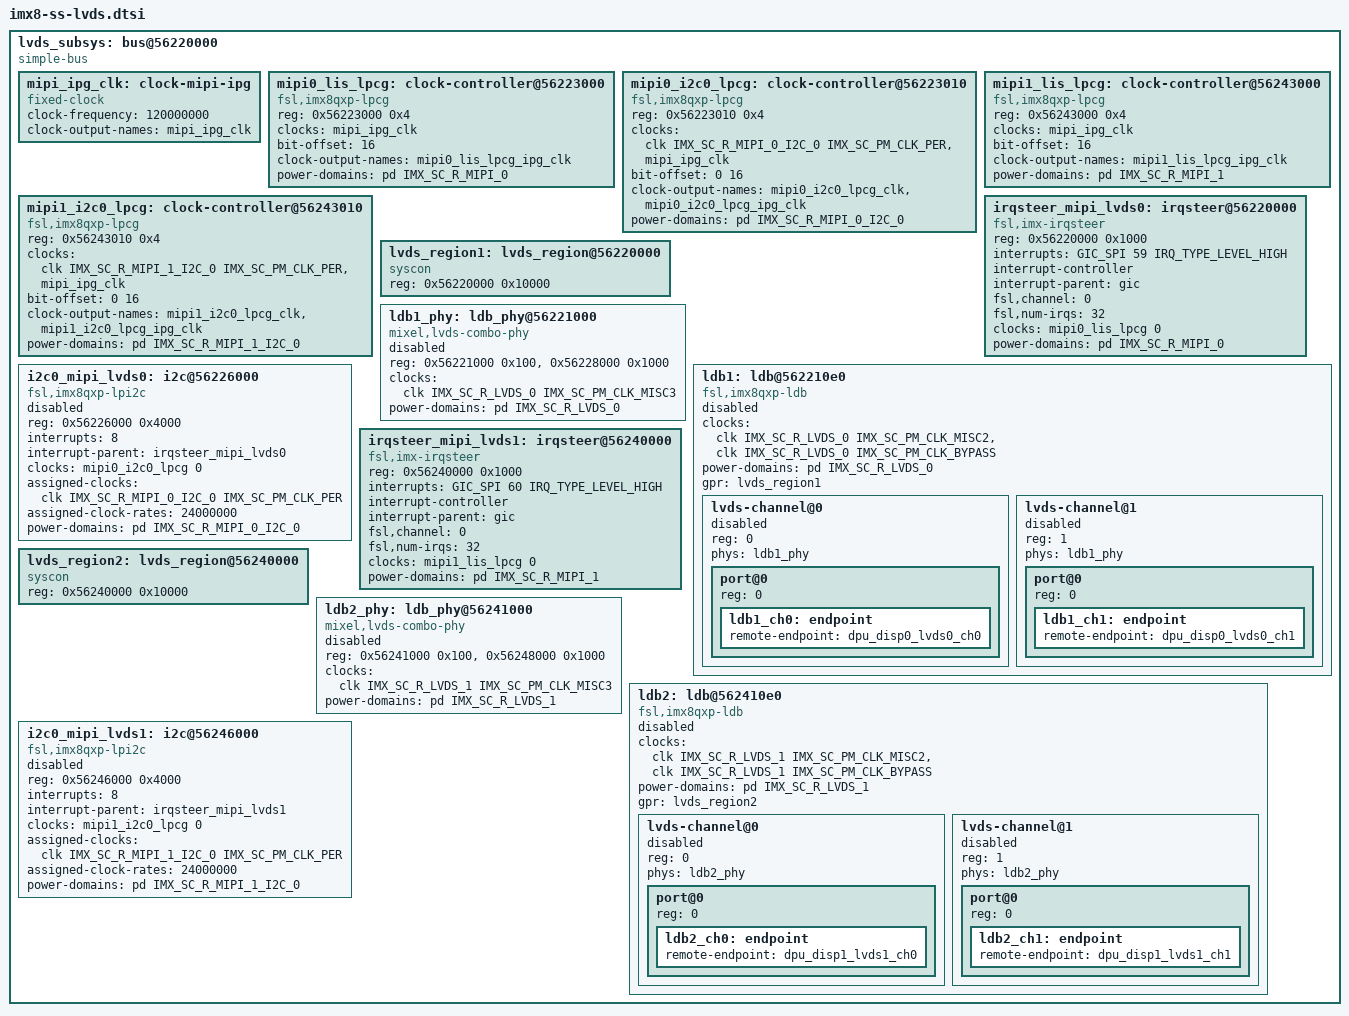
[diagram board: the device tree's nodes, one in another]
// SPDX-License-Identifier: GPL-2.0+
/*
 * Copyright 2019 NXP
 */

lvds_subsys: bus@56220000 {
	compatible = "simple-bus";
	#address-cells = <1>;
	#size-cells = <1>;
	ranges = <0x56220000 0x0 0x56220000 0x30000>;

	mipi_ipg_clk: clock-mipi-ipg {
		compatible = "fixed-clock";
		#clock-cells = <0>;
		clock-frequency = <120000000>;
		clock-output-names = "mipi_ipg_clk";
	};

	mipi0_lis_lpcg: clock-controller@56223000 {
		compatible = "fsl,imx8qxp-lpcg";
		reg = <0x56223000 0x4>;
		#clock-cells = <1>;
		clocks = <&mipi_ipg_clk>;
		bit-offset = <16>;
		clock-output-names = "mipi0_lis_lpcg_ipg_clk";
		power-domains = <&pd IMX_SC_R_MIPI_0>;
	};

	mipi0_i2c0_lpcg: clock-controller@56223010 {
		compatible = "fsl,imx8qxp-lpcg";
		reg = <0x56223010 0x4>;
		#clock-cells = <1>;
		clocks = <&clk IMX_SC_R_MIPI_0_I2C_0 IMX_SC_PM_CLK_PER>,
			 <&mipi_ipg_clk>;
		bit-offset = <0 16>;
		clock-output-names = "mipi0_i2c0_lpcg_clk",
				     "mipi0_i2c0_lpcg_ipg_clk";
		power-domains = <&pd IMX_SC_R_MIPI_0_I2C_0>;
	};

	mipi1_lis_lpcg: clock-controller@56243000 {
		compatible = "fsl,imx8qxp-lpcg";
		reg = <0x56243000 0x4>;
		#clock-cells = <1>;
		clocks = <&mipi_ipg_clk>;
		bit-offset = <16>;
		clock-output-names = "mipi1_lis_lpcg_ipg_clk";
		power-domains = <&pd IMX_SC_R_MIPI_1>;
	};

	mipi1_i2c0_lpcg: clock-controller@56243010 {
		compatible = "fsl,imx8qxp-lpcg";
		reg = <0x56243010 0x4>;
		#clock-cells = <1>;
		clocks = <&clk IMX_SC_R_MIPI_1_I2C_0 IMX_SC_PM_CLK_PER>,
			 <&mipi_ipg_clk>;
		bit-offset = <0 16>;
		clock-output-names = "mipi1_i2c0_lpcg_clk",
				     "mipi1_i2c0_lpcg_ipg_clk";
		power-domains = <&pd IMX_SC_R_MIPI_1_I2C_0>;
	};

	irqsteer_mipi_lvds0: irqsteer@56220000 {
		compatible = "fsl,imx-irqsteer";
		reg = <0x56220000 0x1000>;
		interrupts = <GIC_SPI 59 IRQ_TYPE_LEVEL_HIGH>;
		interrupt-controller;
		interrupt-parent = <&gic>;
		#interrupt-cells = <1>;
		fsl,channel = <0>;
		fsl,num-irqs = <32>;
		clocks = <&mipi0_lis_lpcg 0>;
		clock-names = "ipg";
		power-domains = <&pd IMX_SC_R_MIPI_0>;
	};

	lvds_region1: lvds_region@56220000 {
		compatible = "syscon";
		reg = <0x56220000 0x10000>;
	};

	ldb1_phy: ldb_phy@56221000 {
		compatible = "mixel,lvds-combo-phy";
		reg = <0x56221000 0x100>, <0x56228000 0x1000>;
		#phy-cells = <0>;
		clocks = <&clk IMX_SC_R_LVDS_0 IMX_SC_PM_CLK_MISC3>;
		clock-names = "phy";
		power-domains = <&pd IMX_SC_R_LVDS_0>;
		status = "disabled";
	};

	ldb1: ldb@562210e0 {
		#address-cells = <1>;
		#size-cells = <0>;
		compatible = "fsl,imx8qxp-ldb";
		clocks = <&clk IMX_SC_R_LVDS_0 IMX_SC_PM_CLK_MISC2>,
			 <&clk IMX_SC_R_LVDS_0 IMX_SC_PM_CLK_BYPASS>;
		clock-names = "pixel", "bypass";
		power-domains = <&pd IMX_SC_R_LVDS_0>;
		gpr = <&lvds_region1>;
		status = "disabled";

		lvds-channel@0 {
			#address-cells = <1>;
			#size-cells = <0>;
			reg = <0>;
			phys = <&ldb1_phy>;
			phy-names = "ldb_phy";
			status = "disabled";

			port@0 {
				reg = <0>;

				ldb1_ch0: endpoint {
					remote-endpoint = <&dpu_disp0_lvds0_ch0>;
				};
			};
		};

		lvds-channel@1 {
			#address-cells = <1>;
			#size-cells = <0>;
			reg = <1>;
			phys = <&ldb1_phy>;
			phy-names = "ldb_phy";
			status = "disabled";

			port@0 {
				reg = <0>;

				ldb1_ch1: endpoint {
					remote-endpoint = <&dpu_disp0_lvds0_ch1>;
				};
			};
		};
	};

	i2c0_mipi_lvds0: i2c@56226000 {
		compatible = "fsl,imx8qxp-lpi2c", "fsl,imx7ulp-lpi2c";
		reg = <0x56226000 0x4000>;
		interrupts = <8>;
		interrupt-parent = <&irqsteer_mipi_lvds0>;
		clocks = <&mipi0_i2c0_lpcg 0>;
		clock-names = "per";
		assigned-clocks = <&clk IMX_SC_R_MIPI_0_I2C_0 IMX_SC_PM_CLK_PER>;
		assigned-clock-rates = <24000000>;
		power-domains = <&pd IMX_SC_R_MIPI_0_I2C_0>;
		status = "disabled";
	};

	irqsteer_mipi_lvds1: irqsteer@56240000 {
		compatible = "fsl,imx-irqsteer";
		reg = <0x56240000 0x1000>;
		interrupts = <GIC_SPI 60 IRQ_TYPE_LEVEL_HIGH>;
		interrupt-controller;
		interrupt-parent = <&gic>;
		#interrupt-cells = <1>;
		fsl,channel = <0>;
		fsl,num-irqs = <32>;
		clocks = <&mipi1_lis_lpcg 0>;
		clock-names = "ipg";
		power-domains = <&pd IMX_SC_R_MIPI_1>;
	};

	lvds_region2: lvds_region@56240000 {
		compatible = "syscon";
		reg = <0x56240000 0x10000>;
	};

	ldb2_phy: ldb_phy@56241000 {
		compatible = "mixel,lvds-combo-phy";
		reg = <0x56241000 0x100>, <0x56248000 0x1000>;
		#phy-cells = <0>;
		clocks = <&clk IMX_SC_R_LVDS_1 IMX_SC_PM_CLK_MISC3>;
		clock-names = "phy";
		power-domains = <&pd IMX_SC_R_LVDS_1>;
		status = "disabled";
	};

	ldb2: ldb@562410e0 {
		#address-cells = <1>;
		#size-cells = <0>;
		compatible = "fsl,imx8qxp-ldb";
		clocks = <&clk IMX_SC_R_LVDS_1 IMX_SC_PM_CLK_MISC2>,
			 <&clk IMX_SC_R_LVDS_1 IMX_SC_PM_CLK_BYPASS>;
		clock-names = "pixel", "bypass";
		power-domains = <&pd IMX_SC_R_LVDS_1>;
		gpr = <&lvds_region2>;
		status = "disabled";

		lvds-channel@0 {
			#address-cells = <1>;
			#size-cells = <0>;
			reg = <0>;
			phys = <&ldb2_phy>;
			phy-names = "ldb_phy";
			status = "disabled";

			port@0 {
				reg = <0>;

				ldb2_ch0: endpoint {
					remote-endpoint = <&dpu_disp1_lvds1_ch0>;
				};
			};
		};

		lvds-channel@1 {
			#address-cells = <1>;
			#size-cells = <0>;
			reg = <1>;
			phys = <&ldb2_phy>;
			phy-names = "ldb_phy";
			status = "disabled";

			port@0 {
				reg = <0>;

				ldb2_ch1: endpoint {
					remote-endpoint = <&dpu_disp1_lvds1_ch1>;
				};
			};
		};
	};

	i2c0_mipi_lvds1: i2c@56246000 {
		compatible = "fsl,imx8qxp-lpi2c", "fsl,imx7ulp-lpi2c";
		reg = <0x56246000 0x4000>;
		interrupts = <8>;
		interrupt-parent = <&irqsteer_mipi_lvds1>;
		clocks = <&mipi1_i2c0_lpcg 0>;
		clock-names = "per";
		assigned-clocks = <&clk IMX_SC_R_MIPI_1_I2C_0 IMX_SC_PM_CLK_PER>;
		assigned-clock-rates = <24000000>;
		power-domains = <&pd IMX_SC_R_MIPI_1_I2C_0>;
		status = "disabled";
	};
};
